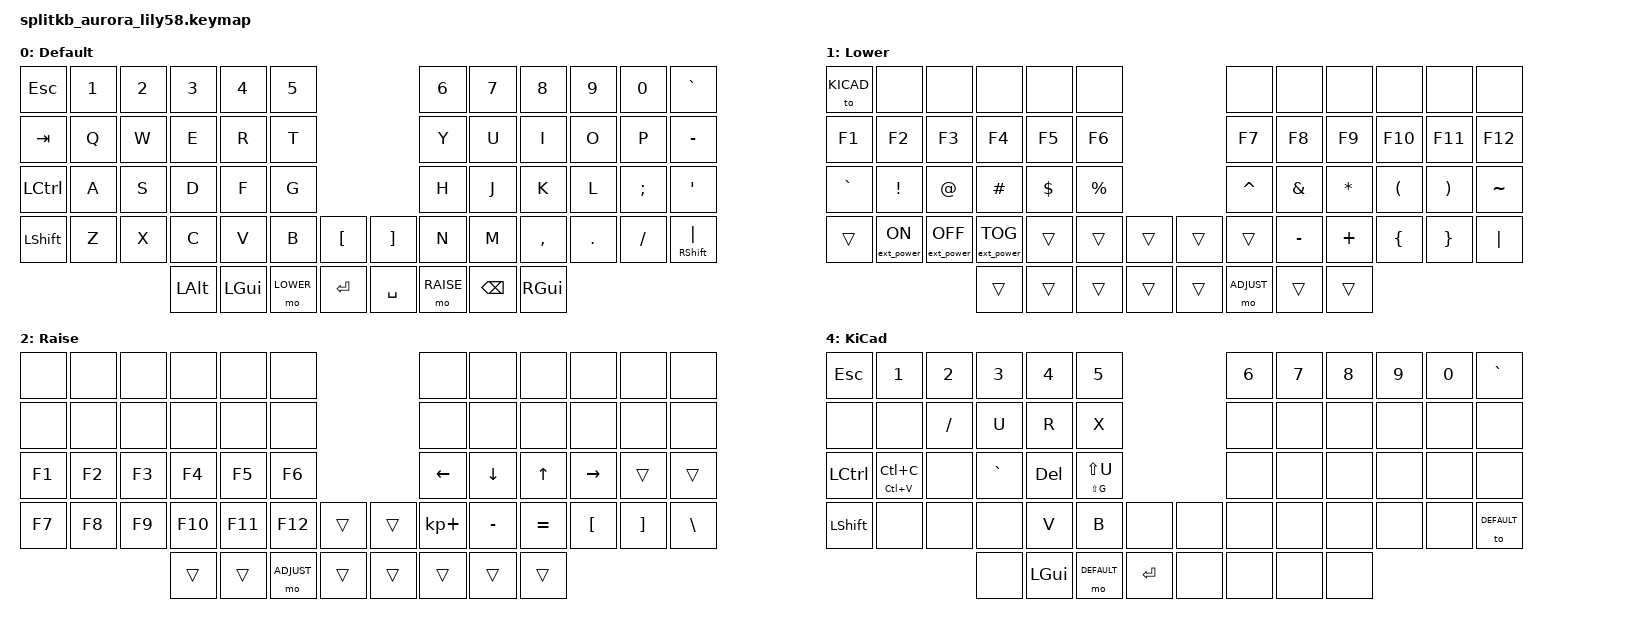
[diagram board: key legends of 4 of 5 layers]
/*
 * Copyright (c) 2022 The ZMK Contributors
 *
 * SPDX-License-Identifier: MIT
 */

#include <behaviors.dtsi>
#include <dt-bindings/zmk/keys.h>
#include <dt-bindings/zmk/bt.h>
#include <dt-bindings/zmk/ext_power.h>

#define DEFAULT 0
#define LOWER   1
#define RAISE   2
#define ADJUST	3
#define KICAD	4

/ {

    keymap {
        compatible = "zmk,keymap";

        default_layer {
            display-name = "Default";
// ,-----------------------------------------.                         ,-----------------------------------------.
// | ESC  |   1  |   2  |   3  |   4  |   5  |                         |   6  |   7  |   8  |   9  |   0  |  `   |
// |------+------+------+------+------+------|                         |------+------+------+------+------+------|
// | Tab  |   Q  |   W  |   E  |   R  |   T  |                         |   Y  |   U  |   I  |   O  |   P  |  -   |
// |------+------+------+------+------+------|                         |------+------+------+------+------+------|
// |LCTRL |   A  |   S  |   D  |   F  |   G  |-------.         ,-------|   H  |   J  |   K  |   L  |   ;  |  '   |
// |------+------+------+------+------+------|   [   |         |    ]  |------+------+------+------+------+------|
// |LShift|   Z  |   X  |   C  |   V  |   B  |-------|         |-------|   N  |   M  |   ,  |   .  |   /  |RSHFT||
// `-----------------------------------------/       /          \      \-----------------------------------------'
//                   | LAlt | LGUI |LOWER | /  Enter/            \Space \  |RAISE |BackSP| RGUI |
//                   |      |      |      |/       /              \      \ |      |      |      |
//                   `----------------------------'                '------''--------------------'
//                                                           
            bindings = <
&kp ESC   &kp N1 &kp N2 &kp N3   &kp N4   &kp N5                           &kp N6     &kp N7   &kp N8    &kp N9  &kp N0   &kp GRAVE
&kp TAB   &kp Q  &kp W  &kp E    &kp R    &kp T                            &kp Y      &kp U    &kp I     &kp O   &kp P    &kp MINUS
&kp LCTRL &kp A  &kp S  &kp D    &kp F    &kp G                            &kp H      &kp J    &kp K     &kp L   &kp SEMI &kp SQT
&kp LSHFT &kp Z  &kp X  &kp C    &kp V    &kp B      &kp LBKT   &kp RBKT   &kp N      &kp M    &kp COMMA &kp DOT &kp FSLH &mt RSHFT PIPE
                        &kp LALT &kp LGUI &mo LOWER  &kp RET    &kp SPACE  &mo RAISE  &kp BSPC &kp RGUI
            >;
        };

        lower_layer {
            display-name = "Lower";
// ,-----------------------------------------.                    ,-----------------------------------------.
// |KICADL|      |      |      |      |      |                    |      |      |      |      |      |      |
// |------+------+------+------+------+------|                    |------+------+------+------+------+------|
// |  F1  |  F2  |  F3  |  F4  |  F5  |  F6  |                    |  F7  |  F8  |  F9  | F10  | F11  | F12  |
// |------+------+------+------+------+------|                    |------+------+------+------+------+------|
// |   `  |   !  |   @  |   #  |   $  |   %  |-------.    ,-------|   ^  |   &  |   *  |   (  |   )  |   -  |
// |------+------+------+------+------+------|   [   |    |    ]  |------+------+------+------+------+------|
// |      |      |      |      |      |      |-------|    |-------|      |   _  |   +  |   {  |   }  |   |  |
// `-----------------------------------------/       /     \      \-----------------------------------------'
//                   | LAlt | LGUI |LOWER | /  Enter/       \Space \  |RAISE |DELETE| RGUI |
//                   |      |      |      |/       /         \      \ |      |      |      |
//                   `----------------------------'           '------''--------------------'
//
            bindings = <
&to KICAD  &none            &none             &none             &none        &none                        &none     &none     &none    &none     &none     &none
&kp F1     &kp F2           &kp F3            &kp F4            &kp F5       &kp F6                       &kp F7    &kp F8    &kp F9   &kp F10   &kp F11   &kp F12
&kp GRAVE  &kp EXCL         &kp AT            &kp HASH          &kp DOLLAR   &kp PRCNT                    &kp CARET &kp AMPS  &kp STAR &kp LPAR  &kp RPAR  &kp TILDE
&trans     &ext_power EP_ON &ext_power EP_OFF &ext_power EP_TOG &trans       &trans    &trans   &trans    &trans    &kp MINUS &kp PLUS &kp LBRC  &kp RBRC  &kp PIPE
                                              &trans            &trans       &trans    &trans   &trans    &mo ADJUST    &trans    &trans
            >;
        };

        raise_layer {
            display-name = "Raise";
// ,-----------------------------------------.                    ,-----------------------------------------.
// |      |      |      |      |      |      |                    |      |      |      |      |      |      |
// |------+------+------+------+------+------|                    |------+------+------+------+------+------|
// |      |      |      |      |      |      |                    |      |      |      |      |      |      |
// |------+------+------+------+------+------|                    |------+------+------+------+------+------|
// |  F1  |  F2  |  F3  |  F4  |  F5  |  F6  |-------.    ,-------| Left | Down |  Up  |Right |      |      |
// |------+------+------+------+------+------|   [   |    |    ]  |------+------+------+------+------+------|
// |  F7  |  F8  |  F9  | F10  | F11  | F12  |-------|    |-------|   +  |   -  |   =  |   [  |   ]  |   \  |
// `-----------------------------------------/       /     \      \-----------------------------------------'
//                   | LAlt | LGUI |LOWER | /  Enter/       \Space \  |RAISE |BackSP| RGUI |
//                   |      |      |      |/       /         \      \ |      |      |      |
//                   `----------------------------'           '------''--------------------'
//
            bindings = <
&none 	  &none  &none  &none   &none   &none                            &none       &none     &none     &none     &none     &none
&none 	  &none  &none  &none   &none   &none                            &none       &none     &none     &none     &none     &none
&kp F1    &kp F2 &kp F3 &kp F4  &kp F5  &kp F6                           &kp LEFT    &kp DOWN  &kp UP    &kp RIGHT &trans    &trans
&kp F7    &kp F8 &kp F9 &kp F10 &kp F11 &kp F12       &trans   &trans    &kp KP_PLUS &kp MINUS &kp EQUAL &kp LBKT  &kp RBKT  &kp BSLH
                        &trans  &trans  &mo ADJUST    &trans   &trans    &trans      &trans    &trans
            >;
        };

        adjust_layer {
            display-name = "Adjust";
// ,-----------------------------------------.                    ,-----------------------------------------.
// |      | MUTE |V_DOWN| V_UP |      |      |                    |      |      |      |      |      |      |
// |------+------+------+------+------+------|                    |------+------+------+------+------+------|
// |      |      |      |      |      |      |                    |      |      |      |      |      |      |
// |------+------+------+------+------+------|                    |------+------+------+------+------+------|
// |BT CLR| BT 1 | BT 2 | BT 3 | BT 4 | BT 5 |-------.    ,-------|      |      |      |      |      |      |
// |------+------+------+------+------+------|       |    |       |------+------+------+------+------+------|
// |      |EPWON |EPWOFF|EPWTOG|      |      |-------|    |-------|      |      |      |      |      |      |
// `-----------------------------------------/       /     \      \-----------------------------------------'
//                   | LAlt | LGUI |LOWER | /  Enter/       \Space \  |RAISE |BackSP| RGUI |
//                   |      |      |      |/       /         \      \ |      |      |      |
//                   `----------------------------'           '------''--------------------'
//	
            bindings = <
&none      &kp C_MUTE       &kp C_VOL_DN      &kp C_VOL_UP      &trans       &trans                       &trans     &trans    &trans    &trans   &trans   &trans
&none 	   &none            &none             &none             &none        &none                        &none      &none     &none     &none    &none    &none
&bt BT_CLR &bt BT_SEL 0     &bt BT_SEL 1      &bt BT_SEL 2      &bt BT_SEL 3 &bt BT_SEL 4                 &kp LS(F1) &none     &none     &none    &none    &none
&none      &ext_power EP_ON &ext_power EP_OFF &ext_power EP_TOG &none        &none    &none     &none 	  &none      &none     &none     &none    &none
                                              &trans            &trans       &none    &trans    &trans    &none      &trans    &trans
            >;
        };
        kicad_layer {
            display-name = "KiCad";
// ,-----------------------------------------.                    ,-----------------------------------------.
// | ESC  |   1  |   2  |   3  |   4  |   5  |                    |   6  |   7  |   8  |   9  |   0  |  `   |
// |------+------+------+------+------+------|                    |------+------+------+------+------+------|
// |      |      |TR COR|TR SEL|ROTATE|TRACK |                    |      |      |      |      |      |      |
// |------+------+------+------+------+------|                    |------+------+------+------+------+------|
// | CTRL |CPYPST|      |NT SEL|DELETE|U/GRP |-------.    ,-------|      |      |      |      |      |      |
// |------+------+------+------+------+------|       |    |       |------+------+------+------+------+------|
// |SHIFT |      |      |      | VIA  |RB ZON|-------|    |-------|      |      |      |      |      |      |
// `-----------------------------------------/       /     \      \-----------------------------------------'
//                   |      | LGUI |DFLT  | /  Enter/       \Space \  |      |BackSP| RGUI |
//                   |      |      |      |/       /         \      \ |      |      |      |
//                   `----------------------------'           '------''--------------------'
//	
            bindings = <
&kp ESC    &kp N1           &kp N2   &kp N3    &kp N4      &kp N5                           	      &kp N6    &kp N7  &kp N8   &kp N9 &kp N0  &kp GRAVE
&none      &none            &kp FSLH &kp U     &kp R       &kp X                                      &none     &none   &none    &none  &none   &none
&kp LCTRL  &mt LC(V) LC(C)  &none    &kp GRAVE &kp DEL     &mt LS(G) LS(U)                            &none     &none   &none    &none  &none   &none
&kp LSHIFT &none            &none    &none     &kp V       &kp B           &none           &none      &none     &none   &none    &none  &none   &to DEFAULT
                                     &none     &kp LGUI    &mo DEFAULT     &kp RET         &none      &none     &none   &none
            >;
        };
    };
};
/*
        _layer {
// ,-----------------------------------------.                    ,-----------------------------------------.
// |      |      |      |      |      |      |                    |      |      |      |      |      |      |
// |------+------+------+------+------+------|                    |------+------+------+------+------+------|
// |      |      |      |      |      |      |                    |      |      |      |      |      |      |
// |------+------+------+------+------+------|                    |------+------+------+------+------+------|
// |      |      |      |      |      |      |-------.    ,-------|      |      |      |      |      |      |
// |------+------+------+------+------+------|       |    |       |------+------+------+------+------+------|
// |      |      |      |      |      |      |-------|    |-------|      |      |      |      |      |      |
// `-----------------------------------------/       /     \      \-----------------------------------------'
//                   |      |      |      | /       /       \      \  |      |      |      |
//                   |      |      |      |/       /         \      \ |      |      |      |
//                   `----------------------------'           '------''--------------------'
//	
            bindings = <
&none   &none  &none  &none    &none   &none                           &none     &none   &none    &none  &none   &none
&none   &none  &none  &none    &none   &none                           &none     &none   &none    &none  &none   &none
&none   &none  &none  &none    &none   &none                           &none     &none   &none    &none  &none   &none
&none   &none  &none  &none    &none   &none    &none       &none      &none     &none   &none    &none  &none   &none
                      &none    &none   &none    &none       &none      &none     &none   &none
            >;
        };
*/
